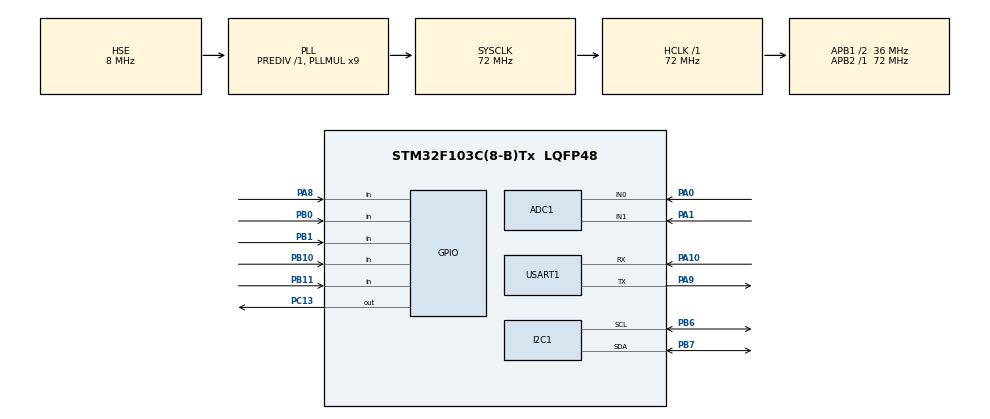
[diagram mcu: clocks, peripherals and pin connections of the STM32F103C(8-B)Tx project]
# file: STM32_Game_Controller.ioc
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ADC1.Channel-0\#ChannelRegularConversion=ADC_CHANNEL_0
ADC1.Channel-2\#ChannelRegularConversion=ADC_CHANNEL_1
ADC1.NbrOfConversion=2
ADC1.NbrOfConversionFlag=1
ADC1.Rank-0\#ChannelRegularConversion=1
ADC1.Rank-2\#ChannelRegularConversion=2
ADC1.SamplingTime-0\#ChannelRegularConversion=ADC_SAMPLETIME_55CYCLES_5
ADC1.SamplingTime-2\#ChannelRegularConversion=ADC_SAMPLETIME_55CYCLES_5
ADC1.master=1
FREERTOS.Tasks01=defaultTask,24,256,StartDefaultTask,Default,NULL,Dynamic,NULL,NULL
FREERTOS.configTOTAL_HEAP_SIZE=8192
FREERTOS.configUSE_DAEMON_TASK_STARTUP_HOOK=1
Mcu.Family=STM32F1
Mcu.Name=STM32F103C(8-B)Tx
Mcu.Package=LQFP48
NVIC.PriorityGroup=NVIC_PRIORITYGROUP_4
NVIC.TIM2_IRQn=true\:15\:0\:false\:false\:true\:false\:false\:true\:true
NVIC.TimeBase=TIM2_IRQn
NVIC.TimeBaseIP=TIM2
PA0-WKUP.Signal=ADCx_IN0
PA1.Signal=ADCx_IN1
PA10.Mode=Asynchronous
PA10.Signal=USART1_RX
PA13.Mode=Serial_Wire
PA13.Signal=SYS_JTMS-SWDIO
PA14.Mode=Serial_Wire
PA14.Signal=SYS_JTCK-SWCLK
PA8.GPIO_PuPd=GPIO_PULLUP
PA8.Signal=GPIO_Input
PA9.Mode=Asynchronous
PA9.Signal=USART1_TX
PB0.GPIO_PuPd=GPIO_PULLUP
PB0.Signal=GPIO_Input
PB1.GPIO_PuPd=GPIO_PULLUP
PB1.Signal=GPIO_Input
PB10.GPIO_PuPd=GPIO_PULLUP
PB10.Signal=GPIO_Input
PB11.GPIO_PuPd=GPIO_PULLUP
PB11.Signal=GPIO_Input
PB6.Mode=I2C
PB6.Signal=I2C1_SCL
PB7.Mode=I2C
PB7.Signal=I2C1_SDA
PC13-TAMPER-RTC.GPIO_PuPd=GPIO_NOPULL
PC13-TAMPER-RTC.PinState=GPIO_PIN_SET
PC13-TAMPER-RTC.Signal=GPIO_Output
PD0-OSC_IN.Mode=HSE-External-Oscillator
PD0-OSC_IN.Signal=RCC_OSC_IN
PD1-OSC_OUT.Mode=HSE-External-Oscillator
PD1-OSC_OUT.Signal=RCC_OSC_OUT
ProjectManager.HeapSize=0x200
ProjectManager.StackSize=0x400
ProjectManager.TargetToolchain=MDK-ARM V5.32
RCC.ADCPresc=RCC_ADCPCLK2_DIV6
RCC.AHBFreq_Value=72000000
RCC.APB1CLKDivider=RCC_HCLK_DIV2
RCC.APB1Freq_Value=36000000
RCC.APB1TimFreq_Value=72000000
RCC.APB2Freq_Value=72000000
RCC.APB2TimFreq_Value=72000000
RCC.HCLKFreq_Value=72000000
RCC.PLLMUL=RCC_PLL_MUL9
RCC.PLLSourceVirtual=RCC_PLLSOURCE_HSE
RCC.SYSCLKFreq_VALUE=72000000
RCC.SYSCLKSource=RCC_SYSCLKSOURCE_PLLCLK
RCC.USBFreq_Value=72000000
SH.ADCx_IN0.0=ADC1_IN0,IN0
SH.ADCx_IN1.0=ADC1_IN1,IN1
USART1.VirtualMode=VM_ASYNC
VP_FREERTOS_VS_CMSIS_V2.Mode=CMSIS_V2
VP_SYS_VS_tim2.Mode=TIM2
board=custom

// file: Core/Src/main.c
/* USER CODE BEGIN Header */
/**
  ******************************************************************************
  * @file           : main.c
  * @brief          : Main program body
  ******************************************************************************
  * @attention
  *
  * Copyright (c) 2026 STMicroelectronics.
  * All rights reserved.
  *
  * This software is licensed under terms that can be found in the LICENSE file
  * in the root directory of this software component.
  * If no LICENSE file comes with this software, it is provided AS-IS.
  *
  ******************************************************************************
  */
/* USER CODE END Header */
#include "main.h"
#include "cmsis_os.h"

ADC_HandleTypeDef hadc1;

I2C_HandleTypeDef hi2c1;

UART_HandleTypeDef huart1;

/* Definitions for defaultTask */
osThreadId_t defaultTaskHandle;
const osThreadAttr_t defaultTask_attributes = {
  .name = "defaultTask",
  .stack_size = 256 * 4,
  .priority = (osPriority_t) osPriorityNormal,
};

void SystemClock_Config(void);
static void MX_GPIO_Init(void);
static void MX_ADC1_Init(void);
static void MX_I2C1_Init(void);
static void MX_USART1_UART_Init(void);
void StartDefaultTask(void *argument);

int main(void)
{

  /* MCU Configuration--------------------------------------------------------*/

  /* Reset of all peripherals, Initializes the Flash interface and the Systick. */
  HAL_Init();

  /* Configure the system clock */
  SystemClock_Config();

  /* Initialize all configured peripherals */
  MX_GPIO_Init();
  MX_ADC1_Init();
  MX_I2C1_Init();
  MX_USART1_UART_Init();

  /* Init scheduler */
  osKernelInitialize();

  /* Create the thread(s) */
  /* creation of defaultTask */
  defaultTaskHandle = osThreadNew(StartDefaultTask, NULL, &defaultTask_attributes);

  /* Start scheduler */
  osKernelStart();

  /* We should never get here as control is now taken by the scheduler */

  /* Infinite loop */
  while (1)
  {

  }
}

void SystemClock_Config(void)
{
  RCC_OscInitTypeDef RCC_OscInitStruct = {0};
  RCC_ClkInitTypeDef RCC_ClkInitStruct = {0};
  RCC_PeriphCLKInitTypeDef PeriphClkInit = {0};

  /** Initializes the RCC Oscillators according to the specified parameters
  * in the RCC_OscInitTypeDef structure.
  */
  RCC_OscInitStruct.OscillatorType = RCC_OSCILLATORTYPE_HSE;
  RCC_OscInitStruct.HSEState = RCC_HSE_ON;
  RCC_OscInitStruct.HSEPredivValue = RCC_HSE_PREDIV_DIV1;
  RCC_OscInitStruct.HSIState = RCC_HSI_ON;
  RCC_OscInitStruct.PLL.PLLState = RCC_PLL_ON;
  RCC_OscInitStruct.PLL.PLLSource = RCC_PLLSOURCE_HSE;
  RCC_OscInitStruct.PLL.PLLMUL = RCC_PLL_MUL9;
  if (HAL_RCC_OscConfig(&RCC_OscInitStruct) != HAL_OK)
  {
    Error_Handler();
  }

  /** Initializes the CPU, AHB and APB buses clocks
  */
  RCC_ClkInitStruct.ClockType = RCC_CLOCKTYPE_HCLK|RCC_CLOCKTYPE_SYSCLK
                              |RCC_CLOCKTYPE_PCLK1|RCC_CLOCKTYPE_PCLK2;
  RCC_ClkInitStruct.SYSCLKSource = RCC_SYSCLKSOURCE_PLLCLK;
  RCC_ClkInitStruct.AHBCLKDivider = RCC_SYSCLK_DIV1;
  RCC_ClkInitStruct.APB1CLKDivider = RCC_HCLK_DIV2;
  RCC_ClkInitStruct.APB2CLKDivider = RCC_HCLK_DIV1;

  if (HAL_RCC_ClockConfig(&RCC_ClkInitStruct, FLASH_LATENCY_2) != HAL_OK)
  {
    Error_Handler();
  }
  PeriphClkInit.PeriphClockSelection = RCC_PERIPHCLK_ADC;
  PeriphClkInit.AdcClockSelection = RCC_ADCPCLK2_DIV6;
  if (HAL_RCCEx_PeriphCLKConfig(&PeriphClkInit) != HAL_OK)
  {
    Error_Handler();
  }
}

static void MX_ADC1_Init(void)
{

  ADC_ChannelConfTypeDef sConfig = {0};

  /** Common config
  */
  hadc1.Instance = ADC1;
  hadc1.Init.ScanConvMode = ADC_SCAN_ENABLE;
  hadc1.Init.ContinuousConvMode = DISABLE;
  hadc1.Init.DiscontinuousConvMode = DISABLE;
  hadc1.Init.ExternalTrigConv = ADC_SOFTWARE_START;
  hadc1.Init.DataAlign = ADC_DATAALIGN_RIGHT;
  hadc1.Init.NbrOfConversion = 2;
  if (HAL_ADC_Init(&hadc1) != HAL_OK)
  {
    Error_Handler();
  }

  /** Configure Regular Channel
  */
  sConfig.Channel = ADC_CHANNEL_0;
  sConfig.Rank = ADC_REGULAR_RANK_1;
  sConfig.SamplingTime = ADC_SAMPLETIME_55CYCLES_5;
  if (HAL_ADC_ConfigChannel(&hadc1, &sConfig) != HAL_OK)
  {
    Error_Handler();
  }

  /** Configure Regular Channel
  */
  sConfig.Channel = ADC_CHANNEL_1;
  sConfig.Rank = ADC_REGULAR_RANK_2;
  if (HAL_ADC_ConfigChannel(&hadc1, &sConfig) != HAL_OK)
  {
    Error_Handler();
  }

}

static void MX_I2C1_Init(void)
{

  hi2c1.Instance = I2C1;
  hi2c1.Init.ClockSpeed = 100000;
  hi2c1.Init.DutyCycle = I2C_DUTYCYCLE_2;
  hi2c1.Init.OwnAddress1 = 0;
  hi2c1.Init.AddressingMode = I2C_ADDRESSINGMODE_7BIT;
  hi2c1.Init.DualAddressMode = I2C_DUALADDRESS_DISABLE;
  hi2c1.Init.OwnAddress2 = 0;
  hi2c1.Init.GeneralCallMode = I2C_GENERALCALL_DISABLE;
  hi2c1.Init.NoStretchMode = I2C_NOSTRETCH_DISABLE;
  if (HAL_I2C_Init(&hi2c1) != HAL_OK)
  {
    Error_Handler();
  }

}

static void MX_USART1_UART_Init(void)
{

  huart1.Instance = USART1;
  huart1.Init.BaudRate = 115200;
  huart1.Init.WordLength = UART_WORDLENGTH_8B;
  huart1.Init.StopBits = UART_STOPBITS_1;
  huart1.Init.Parity = UART_PARITY_NONE;
  huart1.Init.Mode = UART_MODE_TX_RX;
  huart1.Init.HwFlowCtl = UART_HWCONTROL_NONE;
  huart1.Init.OverSampling = UART_OVERSAMPLING_16;
  if (HAL_UART_Init(&huart1) != HAL_OK)
  {
    Error_Handler();
  }

}

static void MX_GPIO_Init(void)
{
  GPIO_InitTypeDef GPIO_InitStruct = {0};

  /* GPIO Ports Clock Enable */
  __HAL_RCC_GPIOC_CLK_ENABLE();
  __HAL_RCC_GPIOD_CLK_ENABLE();
  __HAL_RCC_GPIOA_CLK_ENABLE();
  __HAL_RCC_GPIOB_CLK_ENABLE();

  /*Configure GPIO pin Output Level */
  HAL_GPIO_WritePin(GPIOC, GPIO_PIN_13, GPIO_PIN_SET);

  /*Configure GPIO pin : PC13 */
  GPIO_InitStruct.Pin = GPIO_PIN_13;
  GPIO_InitStruct.Mode = GPIO_MODE_OUTPUT_PP;
  GPIO_InitStruct.Pull = GPIO_NOPULL;
  GPIO_InitStruct.Speed = GPIO_SPEED_FREQ_LOW;
  HAL_GPIO_Init(GPIOC, &GPIO_InitStruct);

  /*Configure GPIO pins : PB0 PB1 PB10 PB11 */
  GPIO_InitStruct.Pin = GPIO_PIN_0|GPIO_PIN_1|GPIO_PIN_10|GPIO_PIN_11;
  GPIO_InitStruct.Mode = GPIO_MODE_INPUT;
  GPIO_InitStruct.Pull = GPIO_PULLUP;
  HAL_GPIO_Init(GPIOB, &GPIO_InitStruct);

  /*Configure GPIO pin : PA8 */
  GPIO_InitStruct.Pin = GPIO_PIN_8;
  GPIO_InitStruct.Mode = GPIO_MODE_INPUT;
  GPIO_InitStruct.Pull = GPIO_PULLUP;
  HAL_GPIO_Init(GPIOA, &GPIO_InitStruct);

}

void StartDefaultTask(void *argument)
{
  /* USER CODE BEGIN 5 */
  /* Infinite loop */
  for(;;)
  {
    HAL_GPIO_TogglePin(GPIOC, GPIO_PIN_13);
    osDelay(500);
  }
  /* USER CODE END 5 */
}

void HAL_TIM_PeriodElapsedCallback(TIM_HandleTypeDef *htim)
{
  if (htim->Instance == TIM2)
  {
    HAL_IncTick();
  }
}

void Error_Handler(void)
{
  __disable_irq();
  while (1)
  {
  }
}

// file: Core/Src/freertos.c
/* USER CODE BEGIN Header */
/**
  ******************************************************************************
  * File Name          : freertos.c
  * Description        : Code for freertos applications
  ******************************************************************************
  * @attention
  *
  * Copyright (c) 2026 STMicroelectronics.
  * All rights reserved.
  *
  * This software is licensed under terms that can be found in the LICENSE file
  * in the root directory of this software component.
  * If no LICENSE file comes with this software, it is provided AS-IS.
  *
  ******************************************************************************
  */
/* USER CODE END Header */

#include "FreeRTOS.h"
#include "task.h"
#include "main.h"

/* USER CODE BEGIN Includes */
#include "rtos_startup.h"

/* USER CODE END Includes */

/* Hook prototypes */
void vApplicationDaemonTaskStartupHook(void);

/* USER CODE BEGIN DAEMON_TASK_STARTUP_HOOK */
void vApplicationDaemonTaskStartupHook(void)
{
  rtos_startup();
}
/* USER CODE END DAEMON_TASK_STARTUP_HOOK */
